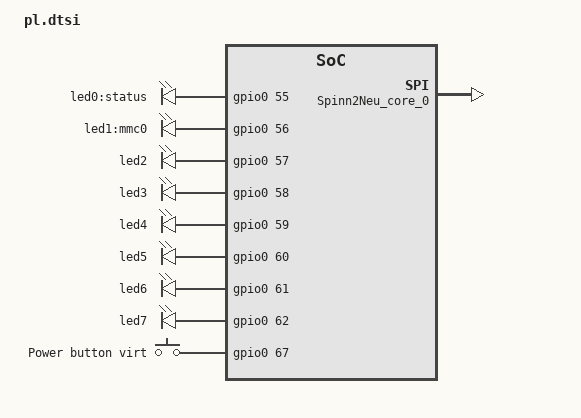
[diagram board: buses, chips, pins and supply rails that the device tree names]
/*
 * CAUTION: This file is automatically generated by Xilinx.
 * Version:  
 * Today is: Tue May 15 12:30:16 2018
 */


/ {
	amba_pl: amba_pl {
		#address-cells = <1>;
		#size-cells = <1>;
		compatible = "simple-bus";
		ranges ;
		Spinn2Neu_core_0: Spinn2Neu_core@43c00000 {
			compatible = "iit.it,Spinn2Neu-core-1.0";
			reg = <0x43c00000 0x10000>;
			interrupt-parent = <&intc>;
			interrupts = <0 31 4>;
			xlnx,debug = "false";
			xlnx,dphase-timeout = <0x8>;
			xlnx,num-mem = <0x1>;
			xlnx,num-reg = <0x18>;
			xlnx,s-axi-min-size = <0x000001FF>;
			xlnx,slv-awidth = <0x20>;
			xlnx,slv-dwidth = <0x20>;
			xlnx,use-wstrb = <0x1>;
		};
		axi_dma_0: dma@40400000 {
			#dma-cells = <1>;
			clock-names = "s_axi_lite_aclk m_axi_sg_aclk m_axi_mm2s_aclk m_axi_s2mm_aclk";
			clocks = "clkc 15>, <&clkc 15>, <&clkc 15>, <&clkc 15";
			compatible = "xlnx,axi-dma-1.00.a";
			interrupt-parent = <&intc>;
			interrupts = <0 29 4 0 30 4>;
			reg = <0x40400000 0x10000>;
			xlnx,addrwidth = <0x20>;
			dma-channel@40400000 {
				compatible = "xlnx,axi-dma-mm2s-channel";
				dma-channels = <0x1>;
				interrupts = <0 29 4>;
				xlnx,datawidth = <0x20>;
				xlnx,device-id = <0x0>;
			};
			dma-channel@40400030 {
				compatible = "xlnx,axi-dma-s2mm-channel";
				dma-channels = <0x1>;
				interrupts = <0 30 4>;
				xlnx,datawidth = <0x20>;
				xlnx,device-id = <0x0>;
			};
		};
        
        leds {
            compatible = "gpio-leds";
            system-status {
                label = "led0:status";
                linux,default-trigger = "heartbeat";
                gpios = <&gpio0 55 0>; /* 0 means Active high */
            };
            led1 {
                label = "led1:mmc0";
                linux,default-trigger = "mmc0";
                gpios = <&gpio0 56 0>;
            };
            led2 {
                gpios = <&gpio0 57 0>;
                default-state = "off";
            };
            led3 {
                gpios = <&gpio0 58 0>;
                default-state = "off";
            };
            led4 {
                gpios = <&gpio0 59 0>;
                default-state = "off";
            };
            led5 {
                gpios = <&gpio0 60 0>;
                default-state = "off";
            };
            led6 {
                gpios = <&gpio0 61 0>;
                default-state = "off";
            };
            led7 {
                gpios = <&gpio0 62 0>;
                default-state = "off";
            };
        } ;

        /*
         * Remember to install acpid
         */
        gpio_keys {
            compatible = "gpio-keys";
            #address-cells = <1>;
            #size-cells = <0>;
            button_at_1 {
                label = "Power button virt";
                /* This is the key power button defined in Linux input.h */
                linux,code = <116>;
                /* EV_KEY */
                linux,input-type = <1>;
                /* 67 means Central Button */
                gpios = <&gpio0 67 0>;
            };
        } ;


	};
};
